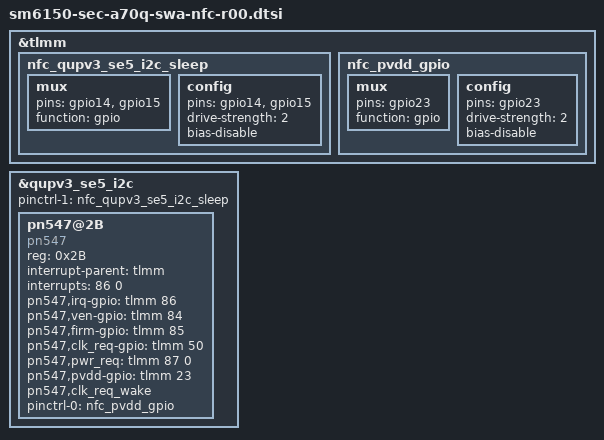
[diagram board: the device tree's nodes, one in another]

/* Copyright (c) 2016-2017, The Linux Foundation. All rights reserved.
 *
 * This program is free software; you can redistribute it and/or modify
 * it under the terms of the GNU General Public License version 2 and
 * only version 2 as published by the Free Software Foundation.
 *
 * This program is distributed in the hope that it will be useful,
 * but WITHOUT ANY WARRANTY; without even the implied warranty of
 * MERCHANTABILITY or FITNESS FOR A PARTICULAR PURPOSE.  See the
 * GNU General Public License for more details.
 */
/*
/ {
	aliases {
		spi1 = &qupv3_se6_spi;
	};
};
*/

&tlmm {
	nfc_qupv3_se5_i2c_sleep: nfc_qupv3_se5_i2c_sleep {
		mux {
			pins = "gpio14", "gpio15";
			function = "gpio";
		};

		config {
			pins = "gpio14", "gpio15";
			drive-strength = <2>;
			bias-disable;
		};
	};
	
	nfc_pvdd_gpio: nfc_pvdd_gpio {
		mux {
			pins = "gpio23";
			function = "gpio";
		};

		config {
			pins = "gpio23";
			drive-strength = <2>;
			bias-disable;
		};
	};
};

/* gpio14 and gpio15 are used for nfc i2c */
&qupv3_se5_i2c { 
	status = "okay";
	pinctrl-1 = <&nfc_qupv3_se5_i2c_sleep>;
	pn547@2B {
		compatible = "pn547";
		reg = <0x2B>;
		interrupt-parent = <&tlmm>;
		interrupts = <86 0>;
		pn547,irq-gpio = <&tlmm 86 0>;
		pn547,ven-gpio = <&tlmm 84 0>;
		pn547,firm-gpio = <&tlmm 85 0>;
		pn547,clk_req-gpio = <&tlmm 50 0>; /* BBCLK3 is controled by gpio 50 */
		pn547,pwr_req =  <&tlmm 87 0>;
		pn547,pvdd-gpio = <&tlmm 23 0>;
		pn547,clk_req_wake;
		pinctrl-names = "default";
		pinctrl-0 = <&nfc_pvdd_gpio>;
	};
};
